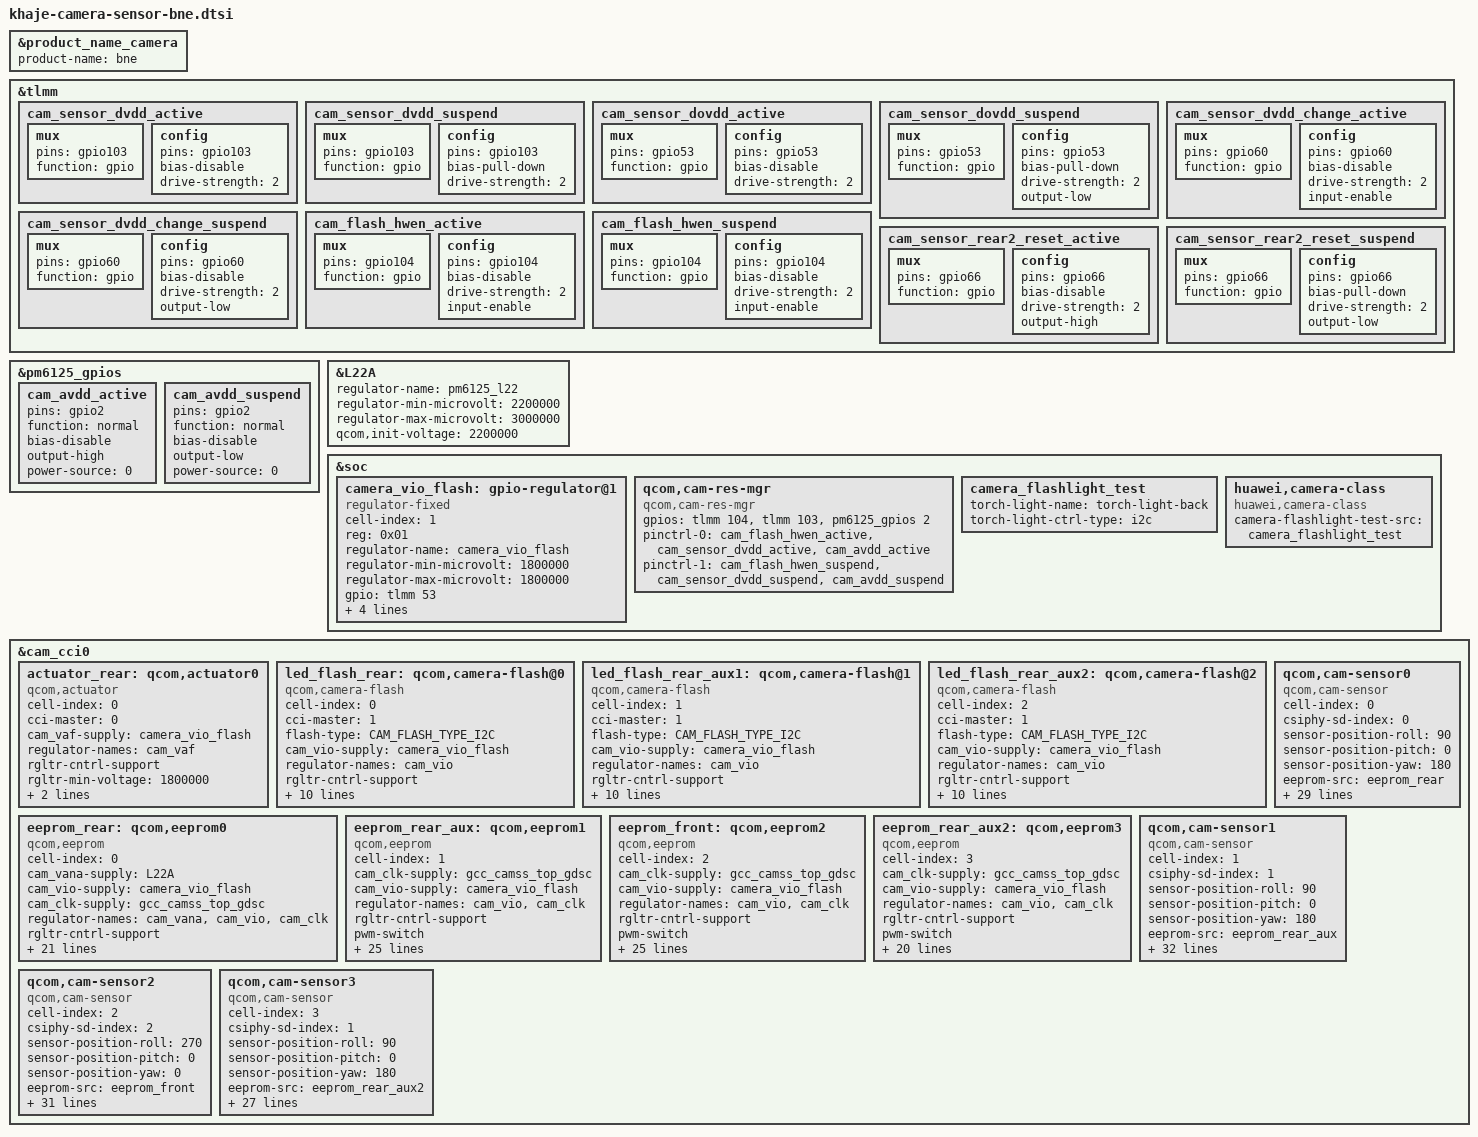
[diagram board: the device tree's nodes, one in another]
#include <dt-bindings/clock/qcom,gcc-khaje.h>
#include <dt-bindings/msm/msm-camera.h>

&product_name_camera {
	product-name = "bne";
};

&tlmm {
		cam_sensor_dvdd_active: cam_sensor_dvdd_active {
			/* front and wide DVDD enable*/
			mux {
				pins = "gpio103";
				function = "gpio";
			};

			config {
				pins = "gpio103";
				bias-disable; /* No PULL */
				drive-strength = <2>; /* 2 MA */
			};
		};

		cam_sensor_dvdd_suspend: cam_sensor_dvdd_suspend {
			/* front and wide DVDD */
			mux {
				pins = "gpio103";
				function = "gpio";
			};

			config {
				pins = "gpio103";
				bias-pull-down; /* PULL DOWN */
				drive-strength = <2>; /* 2 MA */
			};
		};

		cam_sensor_dovdd_active: cam_sensor_dovdd_active {
			/* DOVDD */
			mux {
				pins = "gpio53";
				function = "gpio";
			};

			config {
				pins = "gpio53";
				bias-disable; /* No PULL */
				drive-strength = <2>; /* 2 MA */
			};
		};

		cam_sensor_dovdd_suspend: cam_sensor_dovdd_suspend {
			/* DOVDD */
			mux {
				pins = "gpio53";
				function = "gpio";
			};

			config {
				pins = "gpio53";
				bias-pull-down; /* PULL DOWN */
				drive-strength = <2>; /* 2 MA */
				output-low;
			};
		};

		cam_sensor_dvdd_change_active: cam_sensor_dvdd_change_active {
			/* dvdd_change */
			mux {
				pins = "gpio60";
				function = "gpio";
			};

			config {
				pins = "gpio60";
				bias-disable; /* No PULL */
				drive-strength = <2>; /* 2 MA */
				input-enable;
			};
		};

		cam_sensor_dvdd_change_suspend: cam_sensor_dvdd_change_suspend {
			/* dvdd_change */
			mux {
				pins = "gpio60";
				function = "gpio";
			};

			config {
				pins = "gpio60";
				bias-disable; /* No PULL */
				drive-strength = <2>; /* 2 MA */
				output-low;
			};
		};

		cam_flash_hwen_active: cam_flash_hwen_active {
			/* dvdd_change */
			mux {
				pins = "gpio104";
				function = "gpio";
			};

			config {
				pins = "gpio104";
				bias-disable; /* No PULL */
				drive-strength = <2>; /* 2 MA */
				input-enable;
			};
		};

		cam_flash_hwen_suspend: cam_flash_hwen_suspend {
			/* dvdd_change */
			mux {
				pins = "gpio104";
				function = "gpio";
			};

			config {
				pins = "gpio104";
				bias-disable; /* No PULL */
				drive-strength = <2>; /* 2 MA */
				input-enable;
			};
		};

	cam_sensor_rear2_reset_active: cam_sensor_rear2_reset_active {
		mux {
			pins = "gpio66";
			function = "gpio";
		};

		config {
			pins = "gpio66";
			bias-disable; /* No PULL */
			drive-strength = <2>; /* 2 MA */
			output-high;
		};
	};

	cam_sensor_rear2_reset_suspend: cam_sensor_rear2_reset_suspend {
		mux {
			pins = "gpio66";
			function = "gpio";
		};

		config {
			pins = "gpio66";
			bias-pull-down; /* PULL DOWN*/
			drive-strength = <2>; /* 2 MA */
			output-low;
		};
	};
};

&pm6125_gpios {
	cam_avdd_active: cam_avdd_active {
		pins = "gpio2";
		function = "normal";
		bias-disable;
		output-high;
		power-source = <0>;
	};
	cam_avdd_suspend: cam_avdd_suspend {
		pins = "gpio2";
		function = "normal";
		bias-disable;
		output-low;
		power-source = <0>;
	};
};

&L22A{
	regulator-name = "pm6125_l22";
	regulator-min-microvolt = <2200000>;
	regulator-max-microvolt = <3000000>;
	qcom,init-voltage = <2200000>;
};

&soc {
	camera_vio_flash: gpio-regulator@1 {
		cell-index = <1>;
		compatible = "regulator-fixed";
		reg = <0x01>;
		regulator-name = "camera_vio_flash";
		regulator-min-microvolt = <1800000>;
		regulator-max-microvolt = <1800000>;
		gpio = <&tlmm 53 0>;
		pinctrl-names = "cam_default", "cam_suspend";
		pinctrl-0 = <&cam_sensor_dovdd_active>;
		pinctrl-1 = <&cam_sensor_dovdd_suspend>;
		startup-delay-us = <1000>;
		enable-active-high;
	};

	qcom,cam-res-mgr {
		compatible = "qcom,cam-res-mgr";
		status = "ok";
		gpios = <&tlmm 104 0>,
			<&tlmm 103 0>,
			<&pm6125_gpios 2 0>;
		pinctrl-names = "cam_res_mgr_default", "cam_res_mgr_suspend";
		pinctrl-0 = <&cam_flash_hwen_active
			&cam_sensor_dvdd_active
			&cam_avdd_active>;
		pinctrl-1 = <&cam_flash_hwen_suspend
			&cam_sensor_dvdd_suspend
			&cam_avdd_suspend>;
	};

	camera_flashlight_test: camera_flashlight_test {
			/* torch-light-name can be defined as array,
			for example: torch-light-name = "torch-light-back", "torch-light-front" */
			torch-light-name = "torch-light-back";
			/* Valid values are:  i2c, pmic, gpio ..., the order must same as torch-light-name */
			torch-light-ctrl-type = "i2c";
		};

		huawei,camera-class {
			compatible = "huawei,camera-class";
			camera-flashlight-test-src = <&camera_flashlight_test>;
			status = "ok";
		};
};

&cam_cci0 {
	actuator_rear: qcom,actuator0 {
		cell-index = <0>;
		compatible = "qcom,actuator";
		cci-master = <0>;
		cam_vaf-supply = <&camera_vio_flash>;
		regulator-names = "cam_vaf";
		rgltr-cntrl-support;
		rgltr-min-voltage = <1800000>;
		rgltr-max-voltage = <1800000>;
		rgltr-load-current = <0>;
		status = "ok";
	};

	led_flash_rear: qcom,camera-flash@0 {
		cell-index = <0>;
		compatible = "qcom,camera-flash";
		cci-master = <1>;
		flash-type = <CAM_FLASH_TYPE_I2C>;
		cam_vio-supply = <&camera_vio_flash>;
		regulator-names =  "cam_vio";
		rgltr-cntrl-support;
		pwm-switch;
		rgltr-min-voltage = <1800000>;
		rgltr-max-voltage = <1800000>;
		rgltr-load-current = <0>;
		gpio-no-mux = <0>;
		gpios = <&tlmm 104 0>;
		gpio-custom1 = <0>;
		gpio-req-tbl-num = <0>;
		gpio-req-tbl-flags = <1>;
		gpio-req-tbl-label =  "CUSTOM_FLASH_EN0";
		status = "ok";
	};

	led_flash_rear_aux1: qcom,camera-flash@1 {
		cell-index = <1>;
		compatible = "qcom,camera-flash";
		cci-master = <1>;
		flash-type = <CAM_FLASH_TYPE_I2C>;
		cam_vio-supply = <&camera_vio_flash>;
		regulator-names =  "cam_vio";
		rgltr-cntrl-support;
		pwm-switch;
		rgltr-min-voltage = <1800000>;
		rgltr-max-voltage = <1800000>;
		rgltr-load-current = <0>;
		gpio-no-mux = <0>;
		gpios = <&tlmm 104 0>;
		gpio-custom1 = <0>;
		gpio-req-tbl-num = <0>;
		gpio-req-tbl-flags = <1>;
		gpio-req-tbl-label =  "CUSTOM_FLASH_EN1";
		status = "ok";
	};

	led_flash_rear_aux2: qcom,camera-flash@2 {
		cell-index = <2>;
		compatible = "qcom,camera-flash";
		cci-master = <1>;
		flash-type = <CAM_FLASH_TYPE_I2C>;
		cam_vio-supply = <&camera_vio_flash>;
		regulator-names =  "cam_vio";
		rgltr-cntrl-support;
		pwm-switch;
		rgltr-min-voltage = <1800000>;
		rgltr-max-voltage = <1800000>;
		rgltr-load-current = <0>;
		gpio-no-mux = <0>;
		gpios = <&tlmm 104 0>;
		gpio-custom1 = <0>;
		gpio-req-tbl-num = <0>;
		gpio-req-tbl-flags = <1>;
		gpio-req-tbl-label =  "CUSTOM_FLASH_EN2";
		status = "ok";
	};

	eeprom_rear: qcom,eeprom0 {
		cell-index = <0>;
		compatible = "qcom,eeprom";
		cam_vana-supply = <&L22A>;
		cam_vio-supply = <&camera_vio_flash>;
		cam_clk-supply = <&gcc_camss_top_gdsc>;
		regulator-names = "cam_vana","cam_vio","cam_clk";
		rgltr-cntrl-support;
		pwm-switch;
		rgltr-min-voltage = <2200000 1800000 0>;
		rgltr-max-voltage = <2200000 1800000 0>;
		rgltr-load-current = <80000 0 0>;
		gpio-no-mux = <0>;
		pinctrl-names = "cam_default", "cam_suspend";
		pinctrl-0 = <&cam_sensor_mclk0_active
				&cam_sensor_rear0_reset_active>;
		pinctrl-1 = <&cam_sensor_mclk0_suspend
				&cam_sensor_rear0_reset_suspend>;
		gpios = <&tlmm 20 0>,
			<&tlmm 18 0>,
			<&tlmm 103 0>;
		gpio-reset = <1>;
		gpio-standby = <2>;
		gpio-req-tbl-num = <0 1 2>;
		gpio-req-tbl-flags = <1 0 0>;
		gpio-req-tbl-label = "CAMIF_MCLK0",
					"CAM_RESET0",
					"CAM_VDIG0";
		sensor-mode = <0>;
		cci-master = <0>;
		status = "ok";
		clocks = <&gcc GCC_CAMSS_MCLK0_CLK>;
		clock-names = "cam_clk";
		clock-cntl-level = "turbo";
		clock-rates = <19200000>;
	};

//Rear Aux wide&depth eeprom
	eeprom_rear_aux: qcom,eeprom1 {
		cell-index = <1>;
		compatible = "qcom,eeprom";
		cam_clk-supply = <&gcc_camss_top_gdsc>;
		cam_vio-supply = <&camera_vio_flash>;
		regulator-names =  "cam_vio", "cam_clk";
		rgltr-cntrl-support;
		pwm-switch;
		rgltr-min-voltage = <1800000 0>;
		rgltr-max-voltage = <1800000 0>;
		rgltr-load-current = <0 0>;
		gpio-no-mux = <0>;
		pinctrl-names = "cam_default", "cam_suspend";
		pinctrl-0 = <&cam_sensor_mclk3_active
				&cam_sensor_rear1_reset_active
				&cam_sensor_dvdd_change_suspend>;
		pinctrl-1 = <&cam_sensor_mclk3_suspend
				&cam_sensor_rear1_reset_suspend
				&cam_sensor_dvdd_change_active>;
		gpios = <&tlmm 28 0>,
			<&tlmm 24 0>,
			<&pm6125_gpios 2 0>,
			<&tlmm 103 0>,
			<&tlmm 60 0>;
		gpio-reset = <1>;
		gpio-custom-vana = <2>;
		gpio-custom1 = <3>;
		gpio-custom2 = <4>;
		gpio-req-tbl-num = <0 1 2 3 4>;
		gpio-req-tbl-flags = <1 0 0 0 0>;
		gpio-req-tbl-label = "CAMIF_MCLK1",
					"CAM_RESET1",
					"CAM_AVDD1",
					"CAM_DVDD1",
					"CAM_DVDD_CHANGE1";
		sensor-mode = <0>;
		cci-master = <1>;
		status = "ok";
		clocks = <&gcc GCC_CAMSS_MCLK3_CLK>;
		clock-names = "cam_clk";
		clock-cntl-level = "turbo";
		clock-rates = <19200000>;
	};

	//Front eepom
	eeprom_front: qcom,eeprom2 {
		cell-index = <2>;
		compatible = "qcom,eeprom";
		cam_clk-supply = <&gcc_camss_top_gdsc>;
		cam_vio-supply = <&camera_vio_flash>;
		regulator-names =  "cam_vio", "cam_clk";
		rgltr-cntrl-support;
		pwm-switch;
		rgltr-min-voltage = <1800000 0>;
		rgltr-max-voltage = <1800000 0>;
		rgltr-load-current = <0 0>;
		gpio-no-mux = <0>;
		pinctrl-names = "cam_default", "cam_suspend";
		pinctrl-0 = <&cam_sensor_mclk1_active
				&cam_sensor_front0_reset_active
				&cam_sensor_dvdd_change_active>;
		pinctrl-1 = <&cam_sensor_mclk1_suspend
				&cam_sensor_front0_reset_suspend
				&cam_sensor_dvdd_change_suspend>;
		gpios = <&tlmm 21 0>,
			<&tlmm 19 0>,
			<&pm6125_gpios 2 0>,
			<&tlmm 103 0>,
			<&tlmm 60 0>;
		gpio-reset = <1>;
		gpio-custom-vana = <2>;
		gpio-custom1 = <3>;
		gpio-custom2 = <4>;
		gpio-req-tbl-num = <0 1 2 3 4>;
		gpio-req-tbl-flags = <1 0 0 0 0>;
		gpio-req-tbl-label = "CAMIF_MCLK2",
					"CAM_RESET2",
					"CAM_AVDD2",
					"CAM_DVDD2",
					"CAM_DVDD_CHANGE2";
		sensor-mode = <0>;
		cci-master = <0>;
		status = "ok";
		clocks = <&gcc GCC_CAMSS_MCLK1_CLK>;
		clock-names = "cam_clk";
		clock-cntl-level = "turbo";
		clock-rates = <19200000>;
	};

	//Rear Aux2 macro eeprom
	eeprom_rear_aux2: qcom,eeprom3 {
		cell-index = <3>;
		compatible = "qcom,eeprom";
		cam_clk-supply = <&gcc_camss_top_gdsc>;
		cam_vio-supply = <&camera_vio_flash>;
		regulator-names = "cam_vio", "cam_clk";
		rgltr-cntrl-support;
		pwm-switch;
		rgltr-min-voltage = <1800000 0>;
		rgltr-max-voltage = <1800000 0>;
		rgltr-load-current = <0 0>;
		gpio-no-mux = <0>;
		pinctrl-names = "cam_default", "cam_suspend";
		pinctrl-0 = <&cam_sensor_mclk3_active
				&cam_sensor_rear2_reset_active>;
		pinctrl-1 = <&cam_sensor_mclk3_suspend
				&cam_sensor_rear2_reset_suspend>;
		gpios = <&tlmm 28 0>,
			<&tlmm 66 0>,
			<&pm6125_gpios 2 0>;
		gpio-reset = <1>;
		gpio-custom-vana = <2>;
		gpio-req-tbl-num = <0 1 2>;
		gpio-req-tbl-flags = <1 0 0>;
		gpio-req-tbl-label = "CAMIF_MCLK3",
					"CAM_RESET3",
					"CAM_AVDD3";
		sensor-mode = <0>;
		cci-master = <1>;
		status = "ok";
		clocks = <&gcc GCC_CAMSS_MCLK3_CLK>;
		clock-names = "cam_clk";
		clock-cntl-level = "turbo";
		clock-rates = <19200000>;
	};

// Rear
	qcom,cam-sensor0 {
		cell-index = <0>;
		compatible = "qcom,cam-sensor";
		csiphy-sd-index = <0>;
		sensor-position-roll = <90>;
		sensor-position-pitch = <0>;
		sensor-position-yaw = <180>;
		eeprom-src = <&eeprom_rear>;
		actuator-src = <&actuator_rear>;
		led-flash-src = <&led_flash_rear>;
		cam_vana-supply = <&L22A>;
		cam_vio-supply = <&camera_vio_flash>;
		cam_clk-supply = <&gcc_camss_top_gdsc>;
		regulator-names = "cam_vana","cam_vio","cam_clk";
		rgltr-cntrl-support;
		pwm-switch;
		rgltr-min-voltage = <2200000 1800000 0>;
		rgltr-max-voltage = <2200000 1800000 0>;
		rgltr-load-current = <80000 0 0>;
		gpio-no-mux = <0>;
		pinctrl-names = "cam_default", "cam_suspend";
		pinctrl-0 = <&cam_sensor_mclk0_active
				&cam_sensor_rear0_reset_active>;
		pinctrl-1 = <&cam_sensor_mclk0_suspend
				&cam_sensor_rear0_reset_suspend>;
		gpios = <&tlmm 20 0>,
			<&tlmm 18 0>,
			<&tlmm 103 0>;
		gpio-reset = <1>;
		gpio-standby = <2>;
		gpio-req-tbl-num = <0 1 2>;
		gpio-req-tbl-flags = <1 0 0>;
		gpio-req-tbl-label = "CAMIF_MCLK0",
					"CAM_RESET0",
					"CAM_VDIG0";
		sensor-mode = <0>;
		cci-master = <0>;
		status = "ok";
		clocks = <&gcc GCC_CAMSS_MCLK0_CLK>;
		clock-names = "cam_clk";
		clock-cntl-level = "turbo";
		clock-rates = <19200000>;
		ic_position = <0>; /* CAMERA_POSITION_REAR */
	};

//Rear Aux wide&depth
	qcom,cam-sensor1 {
		cell-index = <1>;
		compatible = "qcom,cam-sensor";
		csiphy-sd-index = <1>;
		sensor-position-roll = <90>;
		sensor-position-pitch = <0>;
		sensor-position-yaw = <180>;
		eeprom-src = <&eeprom_rear_aux>;
		led-flash-src = <&led_flash_rear_aux1>;
		cam_vio-supply = <&camera_vio_flash>;
		cam_clk-supply = <&gcc_camss_top_gdsc>;
		regulator-names = "cam_vio", "cam_clk";
		rgltr-cntrl-support;
		pwm-switch;
		rgltr-min-voltage = <1800000 0>;
		rgltr-max-voltage = <1800000 0>;
		rgltr-load-current = <0 0>;
		gpio-no-mux = <0>;
		pinctrl-names = "cam_default", "cam_suspend";
		pinctrl-0 = <&cam_sensor_mclk3_active
				&cam_sensor_rear1_reset_active
				&cam_sensor_dvdd_change_suspend>;
		pinctrl-1 = <&cam_sensor_mclk3_suspend
				&cam_sensor_rear1_reset_suspend
				&cam_sensor_dvdd_change_active>;
		gpios = <&tlmm 28 0>,
			<&tlmm 24 0>,
			<&pm6125_gpios 2 0>,
			<&tlmm 103 0>,
			<&tlmm 60 0>;
		gpio-reset = <1>;
		gpio-custom-vana = <2>;
		gpio-custom1 = <3>;
		gpio-custom2 = <4>;
		gpio-req-tbl-num = <0 1 2 3 4>;
		gpio-req-tbl-flags = <1 0 0 0 0>;
		gpio-req-tbl-label = "CAMIF_MCLK1",
					"CAM_RESET1",
					"CAM_AVDD1",
					"CAM_DVDD1",
					"CAM_DVDD_CHANGE1";
		sensor-mode = <0>;
		cci-master = <1>;
		status = "ok";
		clocks = <&gcc GCC_CAMSS_MCLK3_CLK>;
		clock-names = "cam_clk";
		clock-cntl-level = "turbo";
		clock-rates = <19200000>;
		ic_position = <2>; /* CAMERA_POSITION_REAR_SECOND */
	};

	//Front
	qcom,cam-sensor2 {
		cell-index = <2>;
		compatible = "qcom,cam-sensor";
		csiphy-sd-index = <2>;
		sensor-position-roll = <270>;
		sensor-position-pitch = <0>;
		sensor-position-yaw = <0>;
		eeprom-src = <&eeprom_front>;
		cam_vio-supply = <&camera_vio_flash>;
		cam_clk-supply = <&gcc_camss_top_gdsc>;
		regulator-names =  "cam_vio", "cam_clk";
		rgltr-cntrl-support;
		pwm-switch;
		rgltr-min-voltage = <1800000 0>;
		rgltr-max-voltage = <1800000 0>;
		rgltr-load-current = <0 0>;
		gpio-no-mux = <0>;
		pinctrl-names = "cam_default", "cam_suspend";
		pinctrl-0 = <&cam_sensor_mclk1_active
				&cam_sensor_front0_reset_active
				&cam_sensor_dvdd_change_active>;
		pinctrl-1 = <&cam_sensor_mclk1_suspend
				&cam_sensor_front0_reset_suspend
				&cam_sensor_dvdd_change_suspend>;
		gpios = <&tlmm 21 0>,
			<&tlmm 19 0>,
			<&pm6125_gpios 2 0>,
			<&tlmm 103 0>,
			<&tlmm 60 0>;
		gpio-reset = <1>;
		gpio-custom-vana = <2>;
		gpio-custom1 = <3>;
		gpio-custom2 = <4>;
		gpio-req-tbl-num = <0 1 2 3 4>;
		gpio-req-tbl-flags = <1 0 0 0 0>;
		gpio-req-tbl-label = "CAMIF_MCLK2",
					"CAM_RESET2",
					"CAM_AVDD2",
					"CAM_DVDD2",
					"CAM_DVDD_CHANGE2";
		sensor-mode = <0>;
		cci-master = <0>;
		status = "ok";
		clocks = <&gcc GCC_CAMSS_MCLK1_CLK>;
		clock-names = "cam_clk";
		clock-cntl-level = "turbo";
		clock-rates = <19200000>;
		ic_position = <1>; /* CAMERA_POSITION_FORE */
	};

	//Rear Aux2 macro
	qcom,cam-sensor3 {
		cell-index = <3>;
		compatible = "qcom,cam-sensor";
		csiphy-sd-index = <1>;
		sensor-position-roll = <90>;
		sensor-position-pitch = <0>;
		sensor-position-yaw = <180>;
		eeprom-src = <&eeprom_rear_aux2>;
		led-flash-src = <&led_flash_rear_aux2>;
		cam_vio-supply = <&camera_vio_flash>;
		cam_clk-supply = <&gcc_camss_top_gdsc>;
		regulator-names =  "cam_vio", "cam_clk";
		rgltr-cntrl-support;
		pwm-switch;
		rgltr-min-voltage = <1800000 0>;
		rgltr-max-voltage = <1800000 0>;
		rgltr-load-current = <0 0>;
		gpio-no-mux = <0>;
		pinctrl-names = "cam_default", "cam_suspend";
		pinctrl-0 = <&cam_sensor_mclk3_active
				&cam_sensor_rear2_reset_active>;
		pinctrl-1 = <&cam_sensor_mclk3_suspend
				&cam_sensor_rear2_reset_suspend>;
		gpios = <&tlmm 28 0>,
			<&tlmm 66 0>,
			<&pm6125_gpios 2 0>;
		gpio-reset = <1>;
		gpio-custom-vana = <2>;
		gpio-req-tbl-num = <0 1 2>;
		gpio-req-tbl-flags = <1 0 0>;
		gpio-req-tbl-label = "CAMIF_MCLK3",
					"CAM_RESET3",
					"CAM_AVDD3";
		sensor-mode = <0>;
		cci-master = <1>;
		status = "ok";
		clocks = <&gcc GCC_CAMSS_MCLK3_CLK>;
		clock-names = "cam_clk";
		clock-cntl-level = "turbo";
		clock-rates = <19200000>;
		ic_position = <4>; /* CAMERA_POSITION_REAR_THIRD */
	};
};
